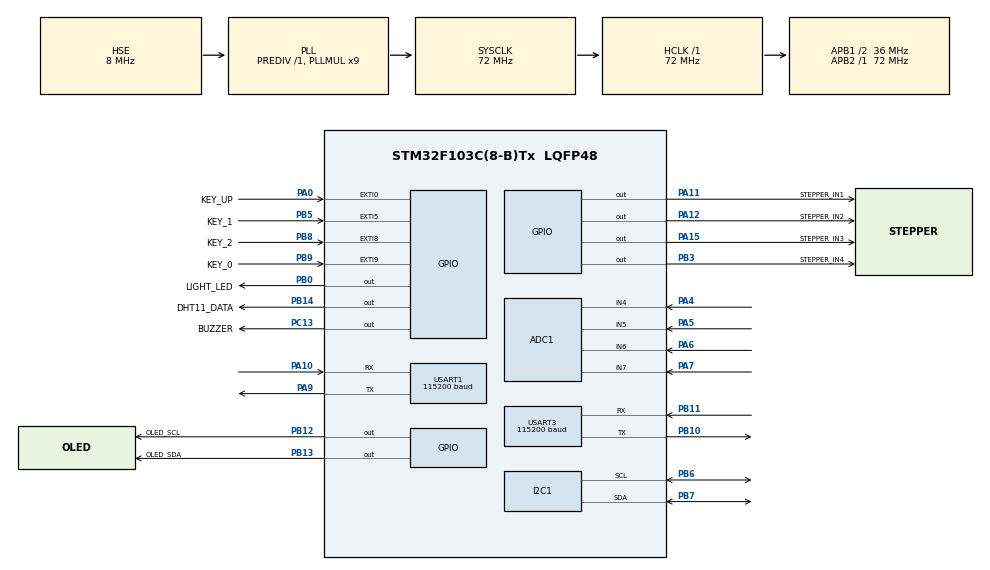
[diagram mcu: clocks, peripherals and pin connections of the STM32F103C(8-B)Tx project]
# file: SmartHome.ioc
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ADC1.Channel-0\#ChannelRegularConversion=ADC_CHANNEL_4
ADC1.Channel-1\#ChannelRegularConversion=ADC_CHANNEL_5
ADC1.Channel-2\#ChannelRegularConversion=ADC_CHANNEL_6
ADC1.Channel-3\#ChannelRegularConversion=ADC_CHANNEL_7
ADC1.ContinuousConvMode=ENABLE
ADC1.DMAContinuousRequests=ENABLE
ADC1.EOCSelection=ADC_EOC_SEQ_CONV
ADC1.NbrOfConversionFlag=1
ADC1.Rank-0\#ChannelRegularConversion=1
ADC1.Rank-1\#ChannelRegularConversion=2
ADC1.Rank-2\#ChannelRegularConversion=3
ADC1.Rank-3\#ChannelRegularConversion=4
ADC1.SamplingTime-0\#ChannelRegularConversion=ADC_SAMPLETIME_55CYCLES_5
ADC1.SamplingTime-1\#ChannelRegularConversion=ADC_SAMPLETIME_55CYCLES_5
ADC1.SamplingTime-2\#ChannelRegularConversion=ADC_SAMPLETIME_55CYCLES_5
ADC1.SamplingTime-3\#ChannelRegularConversion=ADC_SAMPLETIME_55CYCLES_5
ADC1.master=1
Dma.ADC1.0.Direction=DMA_PERIPH_TO_MEMORY
Dma.ADC1.0.Instance=DMA1_Channel1
Dma.ADC1.0.MemDataAlignment=DMA_MDATAALIGN_HALFWORD
Dma.ADC1.0.MemInc=DMA_MINC_ENABLE
Dma.ADC1.0.Mode=DMA_CIRCULAR
Dma.ADC1.0.PeriphDataAlignment=DMA_PDATAALIGN_HALFWORD
Dma.ADC1.0.PeriphInc=DMA_PINC_DISABLE
Dma.ADC1.0.Priority=DMA_PRIORITY_LOW
Dma.Request0=ADC1
FREERTOS.Tasks01=defaultTask,24,128,StartDefaultTask,Default,NULL,Dynamic,NULL,NULL
FREERTOS.configTOTAL_HEAP_SIZE=6144
Mcu.Family=STM32F1
Mcu.Name=STM32F103C(8-B)Tx
Mcu.Package=LQFP48
NVIC.ADC1_2_IRQn=true\:5\:0\:false\:false\:true\:true\:true\:true\:true
NVIC.DMA1_Channel1_IRQn=true\:5\:0\:false\:false\:true\:true\:false\:true\:true
NVIC.PriorityGroup=NVIC_PRIORITYGROUP_4
NVIC.USART1_IRQn=true\:5\:0\:false\:false\:true\:true\:true\:true\:true
NVIC.USART3_IRQn=true\:5\:0\:false\:false\:true\:true\:true\:true\:true
PA0-WKUP.GPIO_Label=KEY_UP
PA0-WKUP.GPIO_ModeDefaultEXTI=GPIO_MODE_IT_FALLING
PA0-WKUP.GPIO_PuPd=GPIO_PULLUP
PA0-WKUP.Signal=GPXTI0
PA10.Mode=Asynchronous
PA10.Signal=USART1_RX
PA11.GPIO_Label=STEPPER_IN1
PA11.GPIO_Speed=GPIO_SPEED_FREQ_LOW
PA11.Signal=GPIO_Output
PA12.GPIO_Label=STEPPER_IN2
PA12.GPIO_Speed=GPIO_SPEED_FREQ_LOW
PA12.Signal=GPIO_Output
PA13.Mode=Serial_Wire
PA13.Signal=SYS_JTMS-SWDIO
PA14.Mode=Serial_Wire
PA14.Signal=SYS_JTCK-SWCLK
PA15.GPIO_Label=STEPPER_IN3
PA15.GPIO_Speed=GPIO_SPEED_FREQ_LOW
PA15.Signal=GPIO_Output
PA4.Signal=ADCx_IN4
PA5.Signal=ADCx_IN5
PA6.Signal=ADCx_IN6
PA7.Signal=ADCx_IN7
PA9.Mode=Asynchronous
PA9.Signal=USART1_TX
PB0.GPIO_Label=LIGHT_LED
PB0.GPIO_Speed=GPIO_SPEED_FREQ_LOW
PB0.Signal=GPIO_Output
PB10.Mode=Asynchronous
PB10.Signal=USART3_TX
PB11.Mode=Asynchronous
PB11.Signal=USART3_RX
PB12.GPIO_Label=OLED_SCL
PB12.GPIO_Mode=GPIO_MODE_OUTPUT_OD
PB12.GPIO_PuPd=GPIO_PULLUP
PB12.GPIO_Speed=GPIO_SPEED_FREQ_HIGH
PB12.Signal=GPIO_Output
PB13.GPIO_Label=OLED_SDA
PB13.GPIO_Mode=GPIO_MODE_OUTPUT_OD
PB13.GPIO_PuPd=GPIO_PULLUP
PB13.GPIO_Speed=GPIO_SPEED_FREQ_HIGH
PB13.Signal=GPIO_Output
PB14.GPIO_Label=DHT11_DATA
PB14.GPIO_Mode=GPIO_MODE_OUTPUT_OD
PB14.GPIO_PuPd=GPIO_PULLUP
PB14.GPIO_Speed=GPIO_SPEED_FREQ_HIGH
PB14.Signal=GPIO_Output
PB3.GPIO_Label=STEPPER_IN4
PB3.GPIO_Speed=GPIO_SPEED_FREQ_LOW
PB3.Signal=GPIO_Output
PB5.GPIO_Label=KEY_1
PB5.GPIO_ModeDefaultEXTI=GPIO_MODE_IT_FALLING
PB5.GPIO_PuPd=GPIO_PULLUP
PB5.Signal=GPXTI5
PB6.Mode=I2C
PB6.Signal=I2C1_SCL
PB7.Mode=I2C
PB7.Signal=I2C1_SDA
PB8.GPIO_Label=KEY_2
PB8.GPIO_ModeDefaultEXTI=GPIO_MODE_IT_FALLING
PB8.GPIO_PuPd=GPIO_PULLUP
PB8.Signal=GPXTI8
PB9.GPIO_Label=KEY_0
PB9.GPIO_ModeDefaultEXTI=GPIO_MODE_IT_FALLING
PB9.GPIO_PuPd=GPIO_PULLUP
PB9.Signal=GPXTI9
PC13-TAMPER-RTC.GPIO_Label=BUZZER
PC13-TAMPER-RTC.GPIO_Speed=GPIO_SPEED_FREQ_LOW
PC13-TAMPER-RTC.Signal=GPIO_Output
PD0-OSC_IN.Mode=HSE-External-Oscillator
PD0-OSC_IN.Signal=RCC_OSC_IN
PD1-OSC_OUT.Mode=HSE-External-Oscillator
PD1-OSC_OUT.Signal=RCC_OSC_OUT
ProjectManager.HeapSize=0x400
ProjectManager.StackSize=0x400
ProjectManager.TargetToolchain=MDK-ARM V5
RCC.ADCPresc=RCC_ADCPCLK2_DIV6
RCC.AHBFreq_Value=72000000
RCC.APB1CLKDivider=RCC_HCLK_DIV2
RCC.APB1Freq_Value=36000000
RCC.APB1TimFreq_Value=72000000
RCC.APB2Freq_Value=72000000
RCC.APB2TimFreq_Value=72000000
RCC.CortexFreq_Value=72000000
RCC.HCLKFreq_Value=72000000
RCC.HSE_VALUE=8000000
RCC.HSE_VALUE_Calculated=8000000
RCC.HSE_VALUE_Custom=8000000
RCC.HSE_VALUE_Custom_Calculated=8000000
RCC.HSE_VALUE_Custom_Resolved=8000000
RCC.HSE_VALUE_Default=8000000
RCC.HSE_VALUE_Resolved=8000000
RCC.PLLMUL=RCC_PLL_MUL9
RCC.PLLSourceVirtual=RCC_PLLSOURCE_HSE
RCC.SYSCLKFreq_VALUE=72000000
RCC.SYSCLKSource=RCC_SYSCLKSOURCE_PLLCLK
RCC.USBFreq_Value=72000000
SH.ADCx_IN4.0=ADC1_IN4,IN4
SH.ADCx_IN5.0=ADC1_IN5,IN5
SH.ADCx_IN6.0=ADC1_IN6,IN6
SH.ADCx_IN7.0=ADC1_IN7,IN7
SYS.Debug=Serial Wire
SYS.TimebaseSource=TIM2
USART1.BaudRate=115200
USART1.Mode=MODE_TX_RX
USART1.VirtualMode=VM_ASYNC
USART3.BaudRate=115200
USART3.Mode=MODE_TX_RX
USART3.VirtualMode=VM_ASYNC
VP_FREERTOS_VS_CMSIS_V1.Mode=CMSIS_V1
board=custom

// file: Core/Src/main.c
/* USER CODE BEGIN Header */
/**
  ******************************************************************************
  * @file           : main.c
  * @brief          : Main program body
  ******************************************************************************
  * @attention
  *
  * Copyright (c) 2026 STMicroelectronics.
  * All rights reserved.
  *
  * This software is licensed under terms that can be found in the LICENSE file
  * in the root directory of this software component.
  * If no LICENSE file comes with this software, it is provided AS-IS.
  *
  ******************************************************************************
  */
/* USER CODE END Header */
#include "main.h"
#include "cmsis_os.h"

/* USER CODE BEGIN Includes */
#include "bsp_board.h"
#include "bsp_stepper.h"
#include "app_main.h"

/* USER CODE END Includes */

ADC_HandleTypeDef hadc1;
DMA_HandleTypeDef hdma_adc1;

I2C_HandleTypeDef hi2c1;

UART_HandleTypeDef huart1;
UART_HandleTypeDef huart3;

osThreadId defaultTaskHandle;

void SystemClock_Config(void);
static void MX_GPIO_Init(void);
static void MX_DMA_Init(void);
static void MX_ADC1_Init(void);
static void MX_I2C1_Init(void);
static void MX_USART1_UART_Init(void);
static void MX_USART3_UART_Init(void);
void StartDefaultTask(void const * argument);

int main(void)
{

  /* MCU Configuration--------------------------------------------------------*/

  /* Reset of all peripherals, Initializes the Flash interface and the Systick. */
  HAL_Init();

  /* Configure the system clock */
  SystemClock_Config();

  /* Initialize all configured peripherals */
  MX_GPIO_Init();
  MX_DMA_Init();
  MX_ADC1_Init();
  MX_I2C1_Init();
  MX_USART1_UART_Init();
  MX_USART3_UART_Init();
  /* USER CODE BEGIN 2 */
  if (BSP_Board_Init() != BSP_OK)
  {
    Error_Handler();
  }
  BSP_Stepper_Init();
  APP_Init();

  /* USER CODE END 2 */

  /* Create the thread(s) */
  /* definition and creation of defaultTask */
  osThreadDef(defaultTask, StartDefaultTask, osPriorityNormal, 0, 128);
  defaultTaskHandle = osThreadCreate(osThread(defaultTask), NULL);

  /* Start scheduler */
  osKernelStart();
  /* We should never get here as control is now taken by the scheduler */
  /* Infinite loop */
  while (1)
  {

  }
}

void SystemClock_Config(void)
{
  RCC_OscInitTypeDef RCC_OscInitStruct = {0};
  RCC_ClkInitTypeDef RCC_ClkInitStruct = {0};
  RCC_PeriphCLKInitTypeDef PeriphClkInit = {0};

  /** Initializes the RCC Oscillators according to the specified parameters
  * in the RCC_OscInitTypeDef structure.
  */
  RCC_OscInitStruct.OscillatorType = RCC_OSCILLATORTYPE_HSE;
  RCC_OscInitStruct.HSEState = RCC_HSE_ON;
  RCC_OscInitStruct.HSEPredivValue = RCC_HSE_PREDIV_DIV1;
  RCC_OscInitStruct.HSIState = RCC_HSI_ON;
  RCC_OscInitStruct.PLL.PLLState = RCC_PLL_ON;
  RCC_OscInitStruct.PLL.PLLSource = RCC_PLLSOURCE_HSE;
  RCC_OscInitStruct.PLL.PLLMUL = RCC_PLL_MUL9;
  if (HAL_RCC_OscConfig(&RCC_OscInitStruct) != HAL_OK)
  {
    Error_Handler();
  }

  /** Initializes the CPU, AHB and APB buses clocks
  */
  RCC_ClkInitStruct.ClockType = RCC_CLOCKTYPE_HCLK|RCC_CLOCKTYPE_SYSCLK
                              |RCC_CLOCKTYPE_PCLK1|RCC_CLOCKTYPE_PCLK2;
  RCC_ClkInitStruct.SYSCLKSource = RCC_SYSCLKSOURCE_PLLCLK;
  RCC_ClkInitStruct.AHBCLKDivider = RCC_SYSCLK_DIV1;
  RCC_ClkInitStruct.APB1CLKDivider = RCC_HCLK_DIV2;
  RCC_ClkInitStruct.APB2CLKDivider = RCC_HCLK_DIV1;

  if (HAL_RCC_ClockConfig(&RCC_ClkInitStruct, FLASH_LATENCY_2) != HAL_OK)
  {
    Error_Handler();
  }
  PeriphClkInit.PeriphClockSelection = RCC_PERIPHCLK_ADC;
  PeriphClkInit.AdcClockSelection = RCC_ADCPCLK2_DIV6;
  if (HAL_RCCEx_PeriphCLKConfig(&PeriphClkInit) != HAL_OK)
  {
    Error_Handler();
  }
}

static void MX_ADC1_Init(void)
{

  ADC_ChannelConfTypeDef sConfig = {0};

  /** Common config
  */
  hadc1.Instance = ADC1;
  hadc1.Init.ScanConvMode = ADC_SCAN_ENABLE;
  hadc1.Init.ContinuousConvMode = ENABLE;
  hadc1.Init.DiscontinuousConvMode = DISABLE;
  hadc1.Init.ExternalTrigConv = ADC_SOFTWARE_START;
  hadc1.Init.DataAlign = ADC_DATAALIGN_RIGHT;
  hadc1.Init.NbrOfConversion = 4;
  if (HAL_ADC_Init(&hadc1) != HAL_OK)
  {
    Error_Handler();
  }

  /** Configure Regular Channel
  */
  sConfig.Channel = ADC_CHANNEL_4;
  sConfig.Rank = ADC_REGULAR_RANK_1;
  sConfig.SamplingTime = ADC_SAMPLETIME_55CYCLES_5;
  if (HAL_ADC_ConfigChannel(&hadc1, &sConfig) != HAL_OK)
  {
    Error_Handler();
  }

  /** Configure Regular Channel
  */
  sConfig.Channel = ADC_CHANNEL_5;
  sConfig.Rank = ADC_REGULAR_RANK_2;
  if (HAL_ADC_ConfigChannel(&hadc1, &sConfig) != HAL_OK)
  {
    Error_Handler();
  }

  /** Configure Regular Channel
  */
  sConfig.Channel = ADC_CHANNEL_6;
  sConfig.Rank = ADC_REGULAR_RANK_3;
  if (HAL_ADC_ConfigChannel(&hadc1, &sConfig) != HAL_OK)
  {
    Error_Handler();
  }

  /** Configure Regular Channel
  */
  sConfig.Channel = ADC_CHANNEL_7;
  sConfig.Rank = ADC_REGULAR_RANK_4;
  if (HAL_ADC_ConfigChannel(&hadc1, &sConfig) != HAL_OK)
  {
    Error_Handler();
  }

}

static void MX_I2C1_Init(void)
{

  hi2c1.Instance = I2C1;
  hi2c1.Init.ClockSpeed = 100000;
  hi2c1.Init.DutyCycle = I2C_DUTYCYCLE_2;
  hi2c1.Init.OwnAddress1 = 0;
  hi2c1.Init.AddressingMode = I2C_ADDRESSINGMODE_7BIT;
  hi2c1.Init.DualAddressMode = I2C_DUALADDRESS_DISABLE;
  hi2c1.Init.OwnAddress2 = 0;
  hi2c1.Init.GeneralCallMode = I2C_GENERALCALL_DISABLE;
  hi2c1.Init.NoStretchMode = I2C_NOSTRETCH_DISABLE;
  if (HAL_I2C_Init(&hi2c1) != HAL_OK)
  {
    Error_Handler();
  }

}

static void MX_USART1_UART_Init(void)
{

  huart1.Instance = USART1;
  huart1.Init.BaudRate = 115200;
  huart1.Init.WordLength = UART_WORDLENGTH_8B;
  huart1.Init.StopBits = UART_STOPBITS_1;
  huart1.Init.Parity = UART_PARITY_NONE;
  huart1.Init.Mode = UART_MODE_TX_RX;
  huart1.Init.HwFlowCtl = UART_HWCONTROL_NONE;
  huart1.Init.OverSampling = UART_OVERSAMPLING_16;
  if (HAL_UART_Init(&huart1) != HAL_OK)
  {
    Error_Handler();
  }

}

static void MX_USART3_UART_Init(void)
{

  huart3.Instance = USART3;
  huart3.Init.BaudRate = 115200;
  huart3.Init.WordLength = UART_WORDLENGTH_8B;
  huart3.Init.StopBits = UART_STOPBITS_1;
  huart3.Init.Parity = UART_PARITY_NONE;
  huart3.Init.Mode = UART_MODE_TX_RX;
  huart3.Init.HwFlowCtl = UART_HWCONTROL_NONE;
  huart3.Init.OverSampling = UART_OVERSAMPLING_16;
  if (HAL_UART_Init(&huart3) != HAL_OK)
  {
    Error_Handler();
  }

}

static void MX_DMA_Init(void)
{

  /* DMA controller clock enable */
  __HAL_RCC_DMA1_CLK_ENABLE();

  /* DMA interrupt init */
  /* DMA1_Channel1_IRQn interrupt configuration */
  HAL_NVIC_SetPriority(DMA1_Channel1_IRQn, 5, 0);
  HAL_NVIC_EnableIRQ(DMA1_Channel1_IRQn);

}

static void MX_GPIO_Init(void)
{
  GPIO_InitTypeDef GPIO_InitStruct = {0};

  /* GPIO Ports Clock Enable */
  __HAL_RCC_GPIOC_CLK_ENABLE();
  __HAL_RCC_GPIOD_CLK_ENABLE();
  __HAL_RCC_GPIOA_CLK_ENABLE();
  __HAL_RCC_GPIOB_CLK_ENABLE();

  /*Configure GPIO pin Output Level */
  HAL_GPIO_WritePin(BUZZER_GPIO_Port, BUZZER_Pin, GPIO_PIN_RESET);

  /*Configure GPIO pin Output Level */
  HAL_GPIO_WritePin(GPIOB, LIGHT_LED_Pin|OLED_SCL_Pin|OLED_SDA_Pin|DHT11_DATA_Pin
                          |STEPPER_IN4_Pin, GPIO_PIN_RESET);

  /*Configure GPIO pin Output Level */
  HAL_GPIO_WritePin(GPIOA, STEPPER_IN1_Pin|STEPPER_IN2_Pin|STEPPER_IN3_Pin, GPIO_PIN_RESET);

  /*Configure GPIO pin : BUZZER_Pin */
  GPIO_InitStruct.Pin = BUZZER_Pin;
  GPIO_InitStruct.Mode = GPIO_MODE_OUTPUT_PP;
  GPIO_InitStruct.Pull = GPIO_NOPULL;
  GPIO_InitStruct.Speed = GPIO_SPEED_FREQ_LOW;
  HAL_GPIO_Init(BUZZER_GPIO_Port, &GPIO_InitStruct);

  /*Configure GPIO pin : KEY_UP_Pin */
  GPIO_InitStruct.Pin = KEY_UP_Pin;
  GPIO_InitStruct.Mode = GPIO_MODE_IT_FALLING;
  GPIO_InitStruct.Pull = GPIO_PULLUP;
  HAL_GPIO_Init(KEY_UP_GPIO_Port, &GPIO_InitStruct);

  /*Configure GPIO pins : LIGHT_LED_Pin STEPPER_IN4_Pin */
  GPIO_InitStruct.Pin = LIGHT_LED_Pin|STEPPER_IN4_Pin;
  GPIO_InitStruct.Mode = GPIO_MODE_OUTPUT_PP;
  GPIO_InitStruct.Pull = GPIO_NOPULL;
  GPIO_InitStruct.Speed = GPIO_SPEED_FREQ_LOW;
  HAL_GPIO_Init(GPIOB, &GPIO_InitStruct);

  /*Configure GPIO pins : OLED_SCL_Pin OLED_SDA_Pin DHT11_DATA_Pin */
  GPIO_InitStruct.Pin = OLED_SCL_Pin|OLED_SDA_Pin|DHT11_DATA_Pin;
  GPIO_InitStruct.Mode = GPIO_MODE_OUTPUT_PP;
  GPIO_InitStruct.Pull = GPIO_PULLUP;
  GPIO_InitStruct.Speed = GPIO_SPEED_FREQ_HIGH;
  HAL_GPIO_Init(GPIOB, &GPIO_InitStruct);

  /*Configure GPIO pins : STEPPER_IN1_Pin STEPPER_IN2_Pin STEPPER_IN3_Pin */
  GPIO_InitStruct.Pin = STEPPER_IN1_Pin|STEPPER_IN2_Pin|STEPPER_IN3_Pin;
  GPIO_InitStruct.Mode = GPIO_MODE_OUTPUT_PP;
  GPIO_InitStruct.Pull = GPIO_NOPULL;
  GPIO_InitStruct.Speed = GPIO_SPEED_FREQ_LOW;
  HAL_GPIO_Init(GPIOA, &GPIO_InitStruct);

  /*Configure GPIO pins : KEY_1_Pin KEY_2_Pin KEY_0_Pin */
  GPIO_InitStruct.Pin = KEY_1_Pin|KEY_2_Pin|KEY_0_Pin;
  GPIO_InitStruct.Mode = GPIO_MODE_IT_FALLING;
  GPIO_InitStruct.Pull = GPIO_PULLUP;
  HAL_GPIO_Init(GPIOB, &GPIO_InitStruct);

}

void StartDefaultTask(void const * argument)
{
  for(;;)
  {
    osDelay(1);
  }
}

void Error_Handler(void)
{
  __disable_irq();
  while (1)
  {
  }
}
